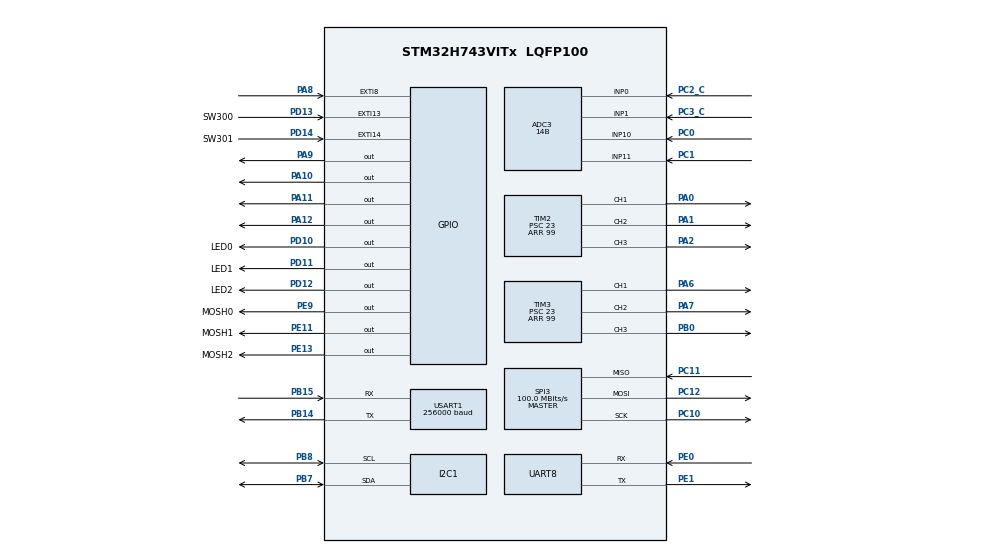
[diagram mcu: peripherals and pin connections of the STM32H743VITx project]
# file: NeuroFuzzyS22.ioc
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ADC3.Channel-1\#ChannelRegularConversion=ADC_CHANNEL_1
ADC3.Channel-2\#ChannelRegularConversion=ADC_CHANNEL_10
ADC3.Channel-3\#ChannelRegularConversion=ADC_CHANNEL_11
ADC3.Channel-4\#ChannelRegularConversion=ADC_CHANNEL_0
ADC3.ContinuousConvMode=ENABLE
ADC3.ConversionDataManagement=ADC_CONVERSIONDATA_DMA_CIRCULAR
ADC3.NbrOfConversion=4
ADC3.NbrOfConversionFlag=1
ADC3.OffsetNumber-1\#ChannelRegularConversion=ADC_OFFSET_NONE
ADC3.OffsetNumber-2\#ChannelRegularConversion=ADC_OFFSET_NONE
ADC3.OffsetNumber-3\#ChannelRegularConversion=ADC_OFFSET_NONE
ADC3.OffsetNumber-4\#ChannelRegularConversion=ADC_OFFSET_NONE
ADC3.OffsetSignedSaturation-1\#ChannelRegularConversion=DISABLE
ADC3.OffsetSignedSaturation-2\#ChannelRegularConversion=DISABLE
ADC3.OffsetSignedSaturation-3\#ChannelRegularConversion=DISABLE
ADC3.Rank-1\#ChannelRegularConversion=1
ADC3.Rank-2\#ChannelRegularConversion=2
ADC3.Rank-3\#ChannelRegularConversion=3
ADC3.Rank-4\#ChannelRegularConversion=4
ADC3.Resolution=ADC_RESOLUTION_14B
ADC3.SamplingTime-1\#ChannelRegularConversion=ADC_SAMPLETIME_1CYCLE_5
ADC3.SamplingTime-2\#ChannelRegularConversion=ADC_SAMPLETIME_1CYCLE_5
ADC3.SamplingTime-3\#ChannelRegularConversion=ADC_SAMPLETIME_1CYCLE_5
ADC3.SamplingTime-4\#ChannelRegularConversion=ADC_SAMPLETIME_1CYCLE_5
Bdma.ADC3.0.Direction=DMA_PERIPH_TO_MEMORY
Bdma.ADC3.0.EventEnable=DISABLE
Bdma.ADC3.0.Instance=BDMA_Channel0
Bdma.ADC3.0.MemDataAlignment=DMA_MDATAALIGN_HALFWORD
Bdma.ADC3.0.MemInc=DMA_MINC_ENABLE
Bdma.ADC3.0.Mode=DMA_CIRCULAR
Bdma.ADC3.0.PeriphDataAlignment=DMA_PDATAALIGN_HALFWORD
Bdma.ADC3.0.PeriphInc=DMA_PINC_DISABLE
Bdma.ADC3.0.Polarity=HAL_DMAMUX_REQ_GEN_RISING
Bdma.ADC3.0.Priority=DMA_PRIORITY_LOW
Bdma.ADC3.0.RequestNumber=1
Bdma.ADC3.0.SignalID=NONE
Bdma.ADC3.0.SyncEnable=DISABLE
Bdma.ADC3.0.SyncPolarity=HAL_DMAMUX_SYNC_NO_EVENT
Bdma.ADC3.0.SyncRequestNumber=1
Bdma.ADC3.0.SyncSignalID=NONE
Bdma.Request0=ADC3
Bdma.RequestsNb=1
CORTEX_M7.default_mode_Activation=1
Dma.Request0=USART1_RX
Dma.Request1=USART1_TX
Dma.USART1_RX.0.Direction=DMA_PERIPH_TO_MEMORY
Dma.USART1_RX.0.EventEnable=DISABLE
Dma.USART1_RX.0.FIFOMode=DMA_FIFOMODE_DISABLE
Dma.USART1_RX.0.Instance=DMA1_Stream0
Dma.USART1_RX.0.MemDataAlignment=DMA_MDATAALIGN_BYTE
Dma.USART1_RX.0.MemInc=DMA_MINC_ENABLE
Dma.USART1_RX.0.Mode=DMA_NORMAL
Dma.USART1_RX.0.PeriphDataAlignment=DMA_PDATAALIGN_BYTE
Dma.USART1_RX.0.PeriphInc=DMA_PINC_DISABLE
Dma.USART1_RX.0.Polarity=HAL_DMAMUX_REQ_GEN_RISING
Dma.USART1_RX.0.Priority=DMA_PRIORITY_LOW
Dma.USART1_RX.0.RequestNumber=1
Dma.USART1_RX.0.SignalID=NONE
Dma.USART1_RX.0.SyncEnable=DISABLE
Dma.USART1_RX.0.SyncPolarity=HAL_DMAMUX_SYNC_NO_EVENT
Dma.USART1_RX.0.SyncRequestNumber=1
Dma.USART1_RX.0.SyncSignalID=NONE
Dma.USART1_TX.1.Direction=DMA_MEMORY_TO_PERIPH
Dma.USART1_TX.1.EventEnable=DISABLE
Dma.USART1_TX.1.FIFOMode=DMA_FIFOMODE_DISABLE
Dma.USART1_TX.1.Instance=DMA1_Stream1
Dma.USART1_TX.1.MemDataAlignment=DMA_MDATAALIGN_BYTE
Dma.USART1_TX.1.MemInc=DMA_MINC_ENABLE
Dma.USART1_TX.1.Mode=DMA_NORMAL
Dma.USART1_TX.1.PeriphDataAlignment=DMA_PDATAALIGN_BYTE
Dma.USART1_TX.1.PeriphInc=DMA_PINC_DISABLE
Dma.USART1_TX.1.Polarity=HAL_DMAMUX_REQ_GEN_RISING
Dma.USART1_TX.1.Priority=DMA_PRIORITY_LOW
Dma.USART1_TX.1.RequestNumber=1
Dma.USART1_TX.1.SignalID=NONE
Dma.USART1_TX.1.SyncEnable=DISABLE
Dma.USART1_TX.1.SyncPolarity=HAL_DMAMUX_SYNC_NO_EVENT
Dma.USART1_TX.1.SyncRequestNumber=1
Dma.USART1_TX.1.SyncSignalID=NONE
FREERTOS.Tasks01=defaultTask,24,128,StartDefaultTask,Default,NULL,Static,defaultTaskBuffer,defaultTaskControlBlock
FREERTOS.configENABLE_FPU=1
FREERTOS.configGENERATE_RUN_TIME_STATS=1
FREERTOS.configUSE_NEWLIB_REENTRANT=1
FREERTOS.configUSE_STATS_FORMATTING_FUNCTIONS=1
I2C1.Timing=0x20A0A3F6
Mcu.Family=STM32H7
Mcu.Name=STM32H743VITx
Mcu.Package=LQFP100
NVIC.BDMA_Channel0_IRQn=true\:5\:0\:false\:false\:true\:true\:false\:true\:true
NVIC.DMA1_Stream0_IRQn=true\:5\:0\:false\:false\:true\:true\:false\:true\:true
NVIC.DMA1_Stream1_IRQn=true\:5\:0\:false\:false\:true\:true\:false\:true\:true
NVIC.EXTI15_10_IRQn=true\:5\:0\:false\:false\:true\:false\:true\:true\:true
NVIC.PriorityGroup=NVIC_PRIORITYGROUP_4
NVIC.TIM16_IRQn=true\:5\:0\:false\:false\:true\:true\:true\:true\:true
NVIC.TIM17_IRQn=true\:15\:0\:false\:false\:true\:false\:false\:true\:true
NVIC.TIM2_IRQn=true\:5\:0\:false\:false\:true\:true\:true\:true\:true
NVIC.TimeBase=TIM17_IRQn
NVIC.TimeBaseIP=TIM17
NVIC.USART1_IRQn=true\:5\:0\:false\:false\:true\:true\:true\:true\:true
PA0.Signal=S_TIM2_CH1_ETR
PA1.Signal=S_TIM2_CH2
PA10.Signal=GPIO_Output
PA11.Signal=GPIO_Output
PA12.Signal=GPIO_Output
PA13\ (JTMS/SWDIO).Mode=Trace_Asynchronous_SW
PA13\ (JTMS/SWDIO).Signal=DEBUG_JTMS-SWDIO
PA14\ (JTCK/SWCLK).Mode=Trace_Asynchronous_SW
PA14\ (JTCK/SWCLK).Signal=DEBUG_JTCK-SWCLK
PA2.Signal=S_TIM2_CH3
PA6.Signal=S_TIM3_CH1
PA7.Signal=S_TIM3_CH2
PA8.Signal=GPXTI8
PA9.Signal=GPIO_Output
PB0.Signal=S_TIM3_CH3
PB14.Mode=Asynchronous
PB14.Signal=USART1_TX
PB15.Mode=Asynchronous
PB15.Signal=USART1_RX
PB3\ (JTDO/TRACESWO).Mode=Trace_Asynchronous_SW
PB3\ (JTDO/TRACESWO).Signal=DEBUG_JTDO-SWO
PB7.Mode=I2C
PB7.Signal=I2C1_SDA
PB8.Mode=I2C
PB8.Signal=I2C1_SCL
PC0.Signal=ADCx_INP10
PC1.Signal=ADCx_INP11
PC10.Mode=Full_Duplex_Master
PC10.Signal=SPI3_SCK
PC11.Mode=Full_Duplex_Master
PC11.Signal=SPI3_MISO
PC12.Mode=Full_Duplex_Master
PC12.Signal=SPI3_MOSI
PC2_C.Mode=IN0-Single-Ended
PC2_C.Signal=ADC3_INP0
PC3_C.Mode=IN1-Single-Ended
PC3_C.Signal=ADC3_INP1
PD10.GPIO_Label=LED0
PD10.GPIO_ModeDefaultOutputPP=GPIO_MODE_OUTPUT_OD
PD10.GPIO_PuPd=GPIO_NOPULL
PD10.GPIO_Speed=GPIO_SPEED_FREQ_VERY_HIGH
PD10.Signal=GPIO_Output
PD11.GPIO_Label=LED1
PD11.GPIO_ModeDefaultOutputPP=GPIO_MODE_OUTPUT_OD
PD11.GPIO_PuPd=GPIO_NOPULL
PD11.GPIO_Speed=GPIO_SPEED_FREQ_VERY_HIGH
PD11.Signal=GPIO_Output
PD12.GPIO_Label=LED2
PD12.GPIO_ModeDefaultOutputPP=GPIO_MODE_OUTPUT_OD
PD12.GPIO_PuPd=GPIO_NOPULL
PD12.GPIO_Speed=GPIO_SPEED_FREQ_VERY_HIGH
PD12.Signal=GPIO_Output
PD13.GPIO_Label=SW300
PD13.GPIO_ModeDefaultEXTI=GPIO_MODE_IT_FALLING
PD13.Signal=GPXTI13
PD14.GPIO_Label=SW301
PD14.GPIO_ModeDefaultEXTI=GPIO_MODE_IT_FALLING
PD14.Signal=GPXTI14
PE0.Mode=Asynchronous
PE0.Signal=UART8_RX
PE1.Mode=Asynchronous
PE1.Signal=UART8_TX
PE11.GPIO_Label=MOSH1
PE11.GPIO_Speed=GPIO_SPEED_FREQ_VERY_HIGH
PE11.Signal=GPIO_Output
PE13.GPIO_Label=MOSH2
PE13.GPIO_Speed=GPIO_SPEED_FREQ_VERY_HIGH
PE13.Signal=GPIO_Output
PE9.GPIO_Label=MOSH0
PE9.GPIO_Speed=GPIO_SPEED_FREQ_VERY_HIGH
PE9.Signal=GPIO_Output
ProjectManager.HeapSize=0x200
ProjectManager.StackSize=0x400
ProjectManager.TargetToolchain=STM32CubeIDE
RCC.ADCFreq_Value=200000000
RCC.APB1Freq_Value=120000000
RCC.APB2Freq_Value=120000000
RCC.APB3Freq_Value=120000000
RCC.APB4Freq_Value=120000000
RCC.CortexFreq_Value=480000000
RCC.D1PPRE=RCC_APB3_DIV2
RCC.D2PPRE1=RCC_APB1_DIV2
RCC.D2PPRE2=RCC_APB2_DIV2
RCC.D3PPRE=RCC_APB4_DIV2
RCC.DIVM1=4
RCC.DIVM2=20
RCC.DIVN1=60
RCC.DIVN2=125
RCC.DIVN3=125
RCC.DIVQ1=5
RCC.DIVR1=4
RCC.HCLKFreq_Value=240000000
RCC.HPRE=RCC_HCLK_DIV2
RCC.I2C123CLockSelection=RCC_I2C123CLKSOURCE_PLL3
RCC.PLLFRACN=0
RCC.SPI123CLockSelection=RCC_SPI123CLKSOURCE_PLL2
RCC.SYSCLKFreq_VALUE=480000000
RCC.SYSCLKSource=RCC_SYSCLKSOURCE_PLLCLK
RCC.USBFreq_Value=192000000
SH.ADCx_INP10.0=ADC3_INP10,IN10-Single-Ended
SH.ADCx_INP11.0=ADC3_INP11,IN11-Single-Ended
SH.S_TIM2_CH1_ETR.0=TIM2_CH1,PWM Generation1 CH1
SH.S_TIM2_CH2.0=TIM2_CH2,PWM Generation2 CH2
SH.S_TIM2_CH3.0=TIM2_CH3,PWM Generation3 CH3
SH.S_TIM3_CH1.0=TIM3_CH1,PWM Generation1 CH1
SH.S_TIM3_CH2.0=TIM3_CH2,PWM Generation2 CH2
SH.S_TIM3_CH3.0=TIM3_CH3,PWM Generation3 CH3
SPI3.BaudRatePrescaler=SPI_BAUDRATEPRESCALER_2
SPI3.CalculateBaudRate=100.0 MBits/s
SPI3.Direction=SPI_DIRECTION_2LINES
SPI3.Mode=SPI_MODE_MASTER
SPI3.VirtualType=VM_MASTER
TIM16.AutoReloadPreload=TIM_AUTORELOAD_PRELOAD_ENABLE
TIM16.Period=44
TIM16.Prescaler=99
TIM2.Channel-PWM\ Generation1\ CH1=TIM_CHANNEL_1
TIM2.Channel-PWM\ Generation2\ CH2=TIM_CHANNEL_2
TIM2.Channel-PWM\ Generation3\ CH3=TIM_CHANNEL_3
TIM2.Period=99
TIM2.Prescaler=23
TIM3.Channel-PWM\ Generation1\ CH1=TIM_CHANNEL_1
TIM3.Channel-PWM\ Generation2\ CH2=TIM_CHANNEL_2
TIM3.Channel-PWM\ Generation3\ CH3=TIM_CHANNEL_3
TIM3.Period=99
TIM3.Prescaler=23
USART1.BaudRate=256000
USART1.VirtualMode-Asynchronous=VM_ASYNC
VP_FREERTOS_VS_CMSIS_V2.Mode=CMSIS_V2
VP_SYS_VS_tim17.Mode=TIM17
VP_TIM16_VS_ClockSourceINT.Mode=Enable_Timer
VP_TIM2_VS_ClockSourceINT.Mode=Internal
VP_TIM3_VS_ClockSourceINT.Mode=Internal
board=custom

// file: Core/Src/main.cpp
/* USER CODE BEGIN Header */
/**
  ******************************************************************************
  * @file           : main.c
  * @brief          : Main program body
  ******************************************************************************
  * @attention
  *
  * Copyright (c) 2022 STMicroelectronics.
  * All rights reserved.
  *
  * This software is licensed under terms that can be found in the LICENSE file
  * in the root directory of this software component.
  * If no LICENSE file comes with this software, it is provided AS-IS.
  *
  ******************************************************************************
  */
/* USER CODE END Header */
#include "main.h"
#include "cmsis_os.h"
#include "adc.h"
#include "bdma.h"
#include "dma.h"
#include "i2c.h"
#include "spi.h"
#include "tim.h"
#include "usart.h"
#include "gpio.h"

/* USER CODE BEGIN Includes */
#include "MemorySpecialAllocators.h"
#include "System.h"
#include "TasksRedirections.h"
/* USER CODE END Includes */

/* USER CODE BEGIN PV */
#ifdef __cplusplus
extern "C" {
#endif
/* USER CODE END PV */

void SystemClock_Config(void);
static void MPU_Config(void);
void MX_FREERTOS_Init(void);
/* USER CODE BEGIN PFP */
#ifdef __cplusplus
}
#endif
/* USER CODE END PFP */

/* USER CODE BEGIN 0 */

NeuroFuzzy::System neuroFuzzySystem MEM_FORCE_D3RAM;
/* USER CODE END 0 */

int main(void) {

    /* MPU Configuration--------------------------------------------------------*/
    MPU_Config();

    /* MCU Configuration--------------------------------------------------------*/

    /* Reset of all peripherals, Initializes the Flash interface and the Systick. */
    HAL_Init();

    /* Configure the system clock */
    SystemClock_Config();

    /* Initialize all configured peripherals */
    MX_GPIO_Init();
    MX_BDMA_Init();
    MX_ADC3_Init();
    MX_DMA_Init();
    MX_USART1_UART_Init();
    MX_TIM2_Init();
    MX_TIM3_Init();
    MX_I2C1_Init();
    MX_SPI3_Init();
    MX_UART8_Init();
    MX_TIM16_Init();

    /* Init scheduler */
    osKernelInitialize();
    MX_FREERTOS_Init();
    traceSTART();

    /* Start scheduler */
    neuroFuzzySystem.init();
    osKernelStart();

    /* We should never get here as control is now taken by the scheduler */
    /* Infinite loop */
    while (1) {

    }
}

void SystemClock_Config(void) {
    RCC_OscInitTypeDef RCC_OscInitStruct = {0};
    RCC_ClkInitTypeDef RCC_ClkInitStruct = {0};

    /** Supply configuration update enable
    */
    HAL_PWREx_ConfigSupply(PWR_LDO_SUPPLY);

    /** Configure the main internal regulator output voltage
    */
    __HAL_PWR_VOLTAGESCALING_CONFIG(PWR_REGULATOR_VOLTAGE_SCALE0);

    while (!__HAL_PWR_GET_FLAG(PWR_FLAG_VOSRDY)) {}

    /** Macro to configure the PLL clock source
    */
    __HAL_RCC_PLL_PLLSOURCE_CONFIG(RCC_PLLSOURCE_HSI);

    /** Initializes the RCC Oscillators according to the specified parameters
    * in the RCC_OscInitTypeDef structure.
    */
    RCC_OscInitStruct.OscillatorType = RCC_OSCILLATORTYPE_HSI;
    RCC_OscInitStruct.HSIState = RCC_HSI_DIV1;
    RCC_OscInitStruct.HSICalibrationValue = RCC_HSICALIBRATION_DEFAULT;
    RCC_OscInitStruct.PLL.PLLState = RCC_PLL_ON;
    RCC_OscInitStruct.PLL.PLLSource = RCC_PLLSOURCE_HSI;
    RCC_OscInitStruct.PLL.PLLM = 4;
    RCC_OscInitStruct.PLL.PLLN = 60;
    RCC_OscInitStruct.PLL.PLLP = 2;
    RCC_OscInitStruct.PLL.PLLQ = 5;
    RCC_OscInitStruct.PLL.PLLR = 4;
    RCC_OscInitStruct.PLL.PLLRGE = RCC_PLL1VCIRANGE_3;
    RCC_OscInitStruct.PLL.PLLVCOSEL = RCC_PLL1VCOWIDE;
    RCC_OscInitStruct.PLL.PLLFRACN = 0;
    if (HAL_RCC_OscConfig(&RCC_OscInitStruct) != HAL_OK) {
        Error_Handler();
    }

    /** Initializes the CPU, AHB and APB buses clocks
    */
    RCC_ClkInitStruct.ClockType = RCC_CLOCKTYPE_HCLK | RCC_CLOCKTYPE_SYSCLK
                                  | RCC_CLOCKTYPE_PCLK1 | RCC_CLOCKTYPE_PCLK2
                                  | RCC_CLOCKTYPE_D3PCLK1 | RCC_CLOCKTYPE_D1PCLK1;
    RCC_ClkInitStruct.SYSCLKSource = RCC_SYSCLKSOURCE_PLLCLK;
    RCC_ClkInitStruct.SYSCLKDivider = RCC_SYSCLK_DIV1;
    RCC_ClkInitStruct.AHBCLKDivider = RCC_HCLK_DIV2;
    RCC_ClkInitStruct.APB3CLKDivider = RCC_APB3_DIV2;
    RCC_ClkInitStruct.APB1CLKDivider = RCC_APB1_DIV2;
    RCC_ClkInitStruct.APB2CLKDivider = RCC_APB2_DIV2;
    RCC_ClkInitStruct.APB4CLKDivider = RCC_APB4_DIV2;

    if (HAL_RCC_ClockConfig(&RCC_ClkInitStruct, FLASH_LATENCY_4) != HAL_OK) {
        Error_Handler();
    }
}

/* MPU Configuration */

void MPU_Config(void) {
    MPU_Region_InitTypeDef MPU_InitStruct = {0};

    /* Disables the MPU */
    HAL_MPU_Disable();

    /** Initializes and configures the Region and the memory to be protected
    */
    MPU_InitStruct.Enable = MPU_REGION_ENABLE;
    MPU_InitStruct.Number = MPU_REGION_NUMBER0;
    MPU_InitStruct.BaseAddress = 0x0;
    MPU_InitStruct.Size = MPU_REGION_SIZE_4GB;
    MPU_InitStruct.SubRegionDisable = 0x87;
    MPU_InitStruct.TypeExtField = MPU_TEX_LEVEL0;
    MPU_InitStruct.AccessPermission = MPU_REGION_NO_ACCESS;
    MPU_InitStruct.DisableExec = MPU_INSTRUCTION_ACCESS_DISABLE;
    MPU_InitStruct.IsShareable = MPU_ACCESS_SHAREABLE;
    MPU_InitStruct.IsCacheable = MPU_ACCESS_NOT_CACHEABLE;
    MPU_InitStruct.IsBufferable = MPU_ACCESS_NOT_BUFFERABLE;

    HAL_MPU_ConfigRegion(&MPU_InitStruct);
    /* Enables the MPU */
    HAL_MPU_Enable(MPU_PRIVILEGED_DEFAULT);

}

void HAL_TIM_PeriodElapsedCallback(TIM_HandleTypeDef *htim) {
    if (htim->Instance == TIM17) {
        HAL_IncTick();
    }
}

void Error_Handler(void) {
    __disable_irq();
    while (1) {
    }
}
